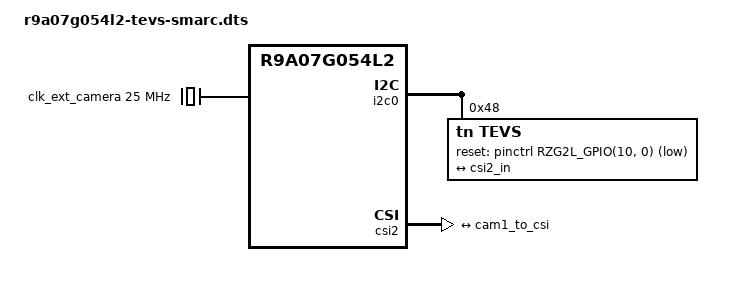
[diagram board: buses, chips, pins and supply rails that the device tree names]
// SPDX-License-Identifier: (GPL-2.0-only OR BSD-2-Clause)
/*
 * Device Tree Source for the RZ/V2L SMARC MXT board variant
 *
 * Copyright (C) 2024 MXT Creation SRL
 */

/dts-v1/;
#include "r9a07g054l2-mxt-smarc.dts"

&clk_ext_camera {
	compatible = "fixed-clock";
	#clock-cells = <0>;
	clock-frequency = <25000000>;
};

&i2c0 {
	pinctrl-0 = <&i2c0_pins>;
	pinctrl-names = "default";

	status = "okay";

	tevs: camera@48 {
		compatible = "tn,tevs";
		reg = <0x48>;

		reset-gpios = <&pinctrl RZG2L_GPIO(10, 0) GPIO_ACTIVE_LOW>;
		continuous-clock = <0>;
		data-lanes = <2>;
		data-frequency = <800>;
		hw-reset; // keep the camera off, when unused

		port {
			cam1_to_csi: endpoint {
				clock-lanes = <0>;
				data-lanes = <1 2>;
				remote-endpoint = <&csi2_in>;
			};
		};
	};

	/delete-node/ camera@3c;
};

&csi2 {
	status = "okay";

	ports {
		port {
			csi2_in: endpoint {
				clock-lanes = <0>;
				data-lanes = <1 2>;
				remote-endpoint = <&cam1_to_csi>;
			};
		};
	};
};

